# AT32F415xx register map
Vendor: Keil; Series: AT32F415; File version: 1.0
CPU: CM4 r0p1, little endian, no MPU, FPU, 4 interrupt priority bits
Registers are 32-bit, read-write, reset 0x0 unless marked. A register's access mark holds for its fields unless they carry their own. Offsets are from the block's base; [hi:lo] are bit positions; {n}, {i} and the like mark numbered series; 'fields as' and 'values as' point back to an identical list.

## ERTC — Real-time clock
Base 0x40002800
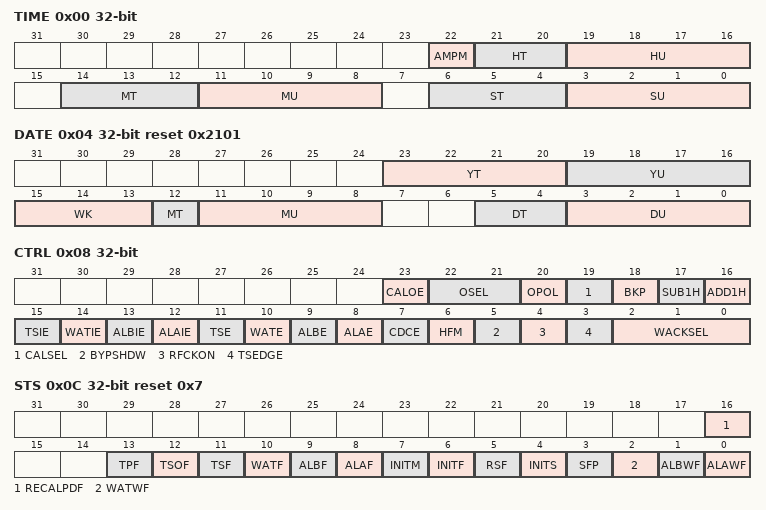
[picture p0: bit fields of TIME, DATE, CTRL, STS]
0x00 TIME
  [22] AMPM — AM/PM notation
  [21:20] HT — Hour tens in BCD format
  [19:16] HU — Hour units in BCD format
  [14:12] MT — Minute tens in BCD format
  [11:8] MU — Minute units in BCD format
  [6:4] ST — Second tens in BCD format
  [3:0] SU — Second units in BCD format
0x04 DATE reset 0x2101
  [23:20] YT — Year tens in BCD format
  [19:16] YU — Year units in BCD format
  [15:13] WK — Week day units
  [12] MT — Month tens in BCD format
  [11:8] MU — Month units in BCD format
  [5:4] DT — Date tens in BCD format
  [3:0] DU — Date units in BCD format
0x08 CTRL — control register
  [23] CALOE — Calibration output enable
  [22:21] OSEL — Output selection
  [20] OPOL — Output polarity
  [19] CALSEL — Calibration output select
  [18] BKP — Backup
  [17] SUB1H — Subtract 1 hour (winter time change)
  [16] ADD1H — Add 1 hour (summer time change)
  [15] TSIE — Time-stamp interrupt enable
  [14] WATIE — Wakeup timer interrupt enable
  [13] ALBIE — Alarm B interrupt enable
  [12] ALAIE — Alarm A interrupt enable
  [11] TSE — Time stamp enable
  [10] WATE — Wakeup timer enable
  [9] ALBE — Alarm B enable
  [8] ALAE — Alarm A enable
  [7] CDCE — Coarse digital calibration enable
  [6] HFM — Hour format
  [5] BYPSHDW — Bypass the shadow registers
  [4] RFCKON — Reference clock detection enable (50 or 60 Hz)
  [3] TSEDGE — Time-stamp event active edge
  [2:0] WACKSEL — Wakeup clock selection
0x0C STS reset 0x7 — initialization and status register
  [16] RECALPDF ro — Recalibration pending Flag
  [13] TPF — Tamper detection flag
  [12] TSOF — Time-stamp overflow flag
  [11] TSF — Time-stamp flag
  [10] WATF — Wakeup timer flag
  [9] ALBF — Alarm B flag
  [8] ALAF — Alarm A flag
  [7] INITM — Initialization mode
  [6] INITF ro — Initialization flag
  [5] RSF — Registers synchronization flag
  [4] INITS ro — Initialization status flag
  [3] SFP — Shift operation pending
  [2] WATWF ro — Wakeup timer write flag
  [1] ALBWF ro — Alarm B write flag
  [0] ALAWF ro — Alarm A write flag
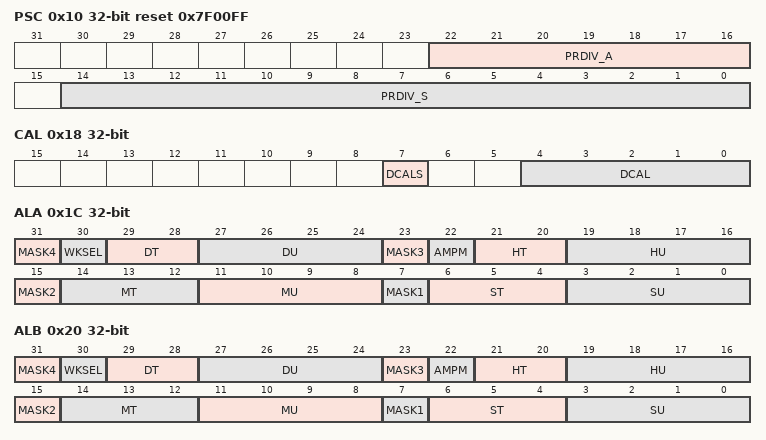
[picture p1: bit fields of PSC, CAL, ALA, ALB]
0x10 PSC reset 0x7F00FF — prescaler register
  [22:16] PRDIV_A — Asynchronous prescaler factor
  [14:0] PRDIV_S — Synchronous prescaler factor
0x14 WATR reset 0xFFFF — wakeup timer register
  [15:0] WAREV — Wakeup auto-reload value bits
0x18 CAL — calibration register
  [7] DCALS — Digital calibration sign
  [4:0] DCAL — Digital calibration
0x1C ALA — alarm A register
  [31] MASK4 — Alarm A date mask
  [30] WKSEL — Week day selection
  [29:28] DT — Date tens in BCD format
  [27:24] DU — Date units or day in BCD format
  [23] MASK3 — Alarm A hours mask
  [22] AMPM — AM/PM notation
  [21:20] HT — Hour tens in BCD format
  [19:16] HU — Hour units in BCD format
  [15] MASK2 — Alarm A minutes mask
  [14:12] MT — Minute tens in BCD format
  [11:8] MU — Minute units in BCD format
  [7] MASK1 — Alarm A seconds mask
  [6:4] ST — Second tens in BCD format
  [3:0] SU — Second units in BCD format
0x20 ALB — alarm B register
  [31] MASK4 — Alarm B date mask
  [30] WKSEL — Week day selection
  [29:28] DT — Date tens in BCD format
  [27:24] DU — Date units or day in BCD format
  [23] MASK3 — Alarm B hours mask
  [22] AMPM — AM/PM notation
  [21:20] HT — Hour tens in BCD format
  [19:16] HU — Hour units in BCD format
  [15] MASK2 — Alarm B minutes mask
  [14:12] MT — Minute tens in BCD format
  [11:8] MU — Minute units in BCD format
  [7] MASK1 — Alarm B seconds mask
  [6:4] ST — Second tens in BCD format
  [3:0] SU — Second units in BCD format
0x24 WPR wo — write protection register
  [7:0] KEY — Write protection key
0x28 SBSR ro — sub second register
  [15:0] SBS — Sub second value
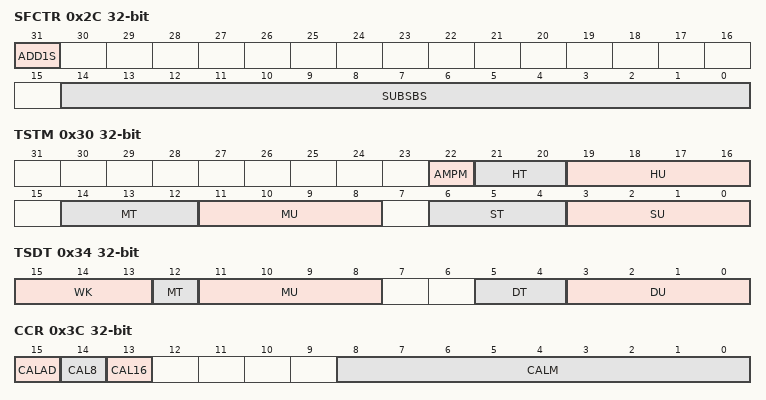
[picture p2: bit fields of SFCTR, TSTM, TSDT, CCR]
0x2C SFCTR wo — shift control register
  [31] ADD1S — Add one second
  [14:0] SUBSBS — Subtract a fraction of a second
0x30 TSTM ro — time stamp time register
  [22] AMPM, [21:20] HT, [19:16] HU, [14:12] MT, [11:8] MU, [6:4] ST, [3:0] SU
0x34 TSDT ro — time stamp date register
  [15:13] WK — Week day units
  [12] MT — Month tens in BCD format
  [11:8] MU — Month units in BCD format
  [5:4] DT — Date tens in BCD format
  [3:0] DU — Date units in BCD format
0x38 TSSBS ro — timestamp sub second register
  [15:0] SBS — Sub second value
0x3C CCR — calibration register
  [15] CALAD — Increase frequency of RTC by 488.5 ppm
  [14] CAL8 — Use an 8-second calibration cycle period
  [13] CAL16 — Use a 16-second calibration cycle period
  [8:0] CALM — Calibration minus
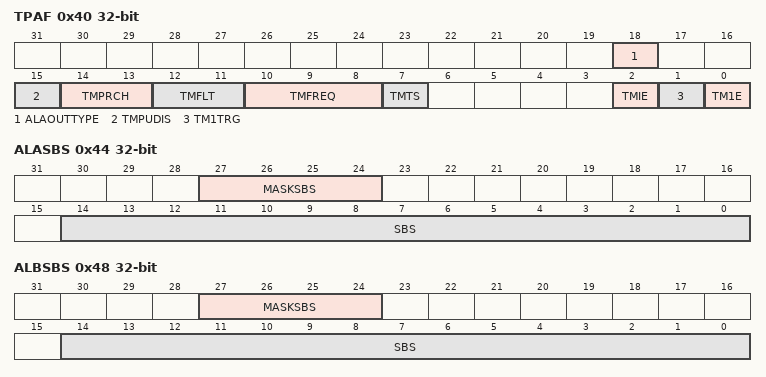
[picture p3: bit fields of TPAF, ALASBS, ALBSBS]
0x40 TPAF — tamper and alternate function configuration register
  [18] ALAOUTTYPE — AFO_ALARM output type
  [15] TMPUDIS — TAMPER pull-up disable
  [14:13] TMPRCH — Tamper precharge duration
  [12:11] TMFLT — Tamper filter count
  [10:8] TMFREQ — Tamper sampling frequency
  [7] TMTS — Activate timestamp on tamper detection event
  [2] TMIE — Tamper interrupt enable
  [1] TM1TRG — Active level for tamper 1
  [0] TM1E — Tamper 1 detection enable
0x44 ALASBS — alarm A sub second register
  [27:24] MASKSBS — Mask the most-significant bits starting at this bit
  [14:0] SBS — Sub seconds value
0x48 ALBSBS — alarm B sub second register
  fields as ALASBS
{0x50+4i} BKP{i}DT (i=0..19) — Backup register
  [31:0] D — Backup data
